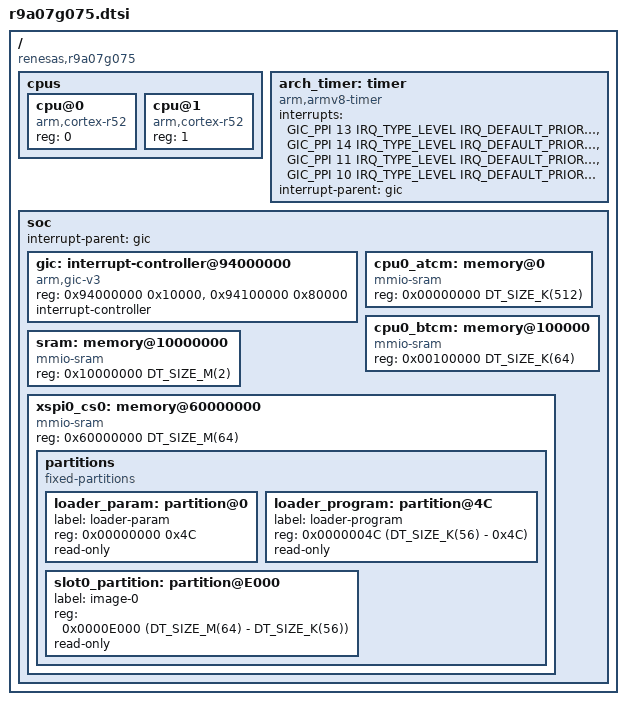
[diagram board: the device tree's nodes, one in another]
/*
 * Copyright (c) 2023 Antmicro <www.antmicro.com>
 * Copyright (c) 2025 Renesas Electronics Corporation
 *
 * SPDX-License-Identifier: Apache-2.0
 */

#include <mem.h>
#include <arm/armv8-r.dtsi>
#include <zephyr/dt-bindings/interrupt-controller/arm-gic.h>

/ {
	compatible = "renesas,r9a07g075";
	#address-cells = <1>;
	#size-cells = <1>;

	cpus {
		#address-cells = <1>;
		#size-cells = <0>;

		cpu@0 {
			device_type = "cpu";
			compatible = "arm,cortex-r52";
			reg = <0>;
		};

		cpu@1 {
			device_type = "cpu";
			compatible = "arm,cortex-r52";
			reg = <1>;
		};
	};

	arch_timer: timer {
		compatible = "arm,armv8-timer";
		interrupts = <GIC_PPI 13 IRQ_TYPE_LEVEL IRQ_DEFAULT_PRIORITY>,
				<GIC_PPI 14 IRQ_TYPE_LEVEL IRQ_DEFAULT_PRIORITY>,
				<GIC_PPI 11 IRQ_TYPE_LEVEL IRQ_DEFAULT_PRIORITY>,
				<GIC_PPI 10 IRQ_TYPE_LEVEL IRQ_DEFAULT_PRIORITY>;
		interrupt-parent = <&gic>;
	};

	soc {
		interrupt-parent = <&gic>;

		gic: interrupt-controller@94000000 {
			compatible = "arm,gic-v3", "arm,gic";
			reg = <0x94000000 0x10000>,
				<0x94100000 0x80000>;
			interrupt-controller;
			#interrupt-cells = <4>;
			status = "okay";
		};

		cpu0_atcm: memory@0 {
			compatible = "mmio-sram";
			reg = <0x00000000 DT_SIZE_K(512)>;
		};

		cpu0_btcm: memory@100000 {
			compatible = "mmio-sram";
			reg = <0x00100000 DT_SIZE_K(64)>;
		};

		sram: memory@10000000 {
			compatible = "mmio-sram";
			reg = <0x10000000 DT_SIZE_M(2)>;
		};

		xspi0_cs0: memory@60000000 {
			compatible = "mmio-sram";
			reg = <0x60000000 DT_SIZE_M(64)>;

			partitions {
				compatible = "fixed-partitions";
				#address-cells = <1>;
				#size-cells = <1>;
				loader_param: partition@0 {
					label = "loader-param";
					reg = <0x00000000 0x4C>;
					read-only;
				};

				loader_program: partition@4C {
					label = "loader-program";
					reg = <0x0000004C (DT_SIZE_K(56) - 0x4C)>;
					read-only;
				};

				slot0_partition: partition@E000 {
					label = "image-0";
					reg = <0x0000E000 (DT_SIZE_M(64) - DT_SIZE_K(56))>;
					read-only;
				};
			};
		};
	};
};
